# ESP32-H4 register map
Vendor: ESPRESSIF SYSTEMS (SHANGHAI) CO., LTD.; Series: ESP32 H-Series; File version: 1
CPU: RV32IMAC r0p0, little endian, no MPU, no FPU, 0 interrupt priority bits
Address unit: 32 bits
Registers are 32-bit, read-write, reset 0x0 unless marked. A register's access mark holds for its fields unless they carry their own. Offsets are from the block's base; [hi:lo] are bit positions.

## LP_PERI — LP_PERI Peripheral
Base 0x600B3400
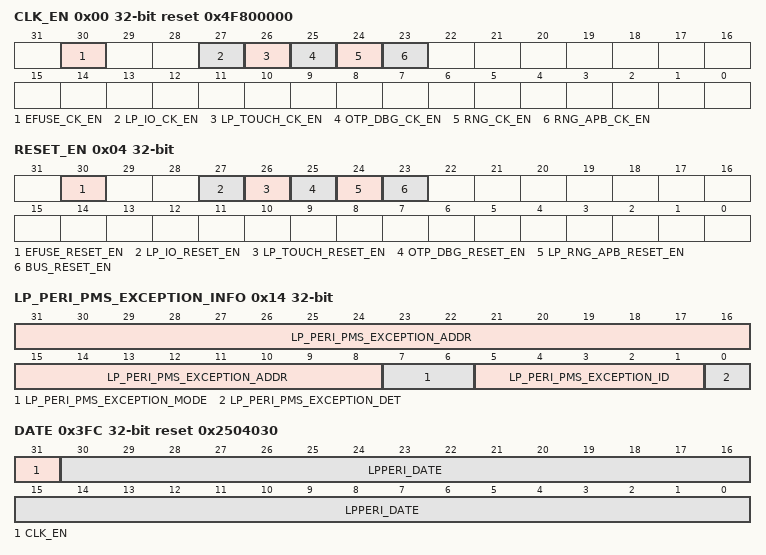
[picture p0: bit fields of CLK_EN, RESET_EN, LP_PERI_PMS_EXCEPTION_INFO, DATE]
0x00 CLK_EN reset 0x4F800000 — configure peri in lp system clk enable
  [30] EFUSE_CK_EN — efuse core clk enable 1: enable clock 0: disable clock
  [27] LP_IO_CK_EN — lp io clk enable 1: enable clock 0: disable clock
  [26] LP_TOUCH_CK_EN — lp touch clk enable 1: enable clock 0: disable clock
  [25] OTP_DBG_CK_EN — lp optdebug clk enable 1: enable clock 0: disable clock
  [24] RNG_CK_EN — lp rng clk enable 1: enable clock 0: disable clock
  [23] RNG_APB_CK_EN — lp rng apb clk enable 1: enable clock 0: disable clock
0x04 RESET_EN access per field — configure peri in lp system reset enable
  [30] EFUSE_RESET_EN rw — efuse core reset enable 1: enable reset 0: disable reset
  [27] LP_IO_RESET_EN rw — lp io reset enable 1: enable reset 0: disable reset
  [26] LP_TOUCH_RESET_EN rw — lp touch reset enable 1: enable reset 0: disable reset
  [25] OTP_DBG_RESET_EN rw — lp optdebug reset enable 1: enable reset 0: disable reset
  [24] LP_RNG_APB_RESET_EN rw — lp rng apb reset enable 1: enable reset 0: disable reset
  [23] BUS_RESET_EN wo — lp bus reset enable 1: enable reset 0: disable reset
0x10 LP_PERI_PMS_CONF wo — LP Peripherals PMS configuration register
  [0] LP_PERI_PMS_EXCEPTION_CLR — Configures whether or not to clear lp peri_pms_record_reg.\\ 0: No clear\\ 1: Clear peri_pms_record_reg\\
0x14 LP_PERI_PMS_EXCEPTION_INFO ro — LP Peripherals PMS exception info record register
  [31:8] LP_PERI_PMS_EXCEPTION_ADDR — Represents the access address (bit23~bit0) when lp peripheral pms has been triggered.\\
  [7:6] LP_PERI_PMS_EXCEPTION_MODE — Represents the security mode when lp peripheral pms has been triggered.\\
  [5:1] LP_PERI_PMS_EXCEPTION_ID — Represents the master id when lp peripheral pms has been triggered.\\
  [0] LP_PERI_PMS_EXCEPTION_DET — Represents whether the lp peripheral pms has been triggered.\\ 0: No triggered\\ 1: Has been triggered\\
0x18 PERI_PMS_INT_EN — APM interrupt enable register
  [0] LP_PERI_PMS_INT_EN — Configures to enable lp peri pms interrupt.\\ 0: disable \\ 1: enable \\
0x20 INTERRUPT_SOURCE ro — record the lp cpu interrupt
  [4:0] LP_INTERRUPT_SOURCE — BIT4~BIT0: pmu_lp_int, modem_lp_int, lp_timer_lp_int, lp_analog_peri_int, lp_io_int
0x3FC DATE reset 0x2504030 — version register
  [31] CLK_EN — force on reg clk
  [30:0] LPPERI_DATE — version register

## LP_ANA — LP_ANA Peripheral
Base 0x600B2C00
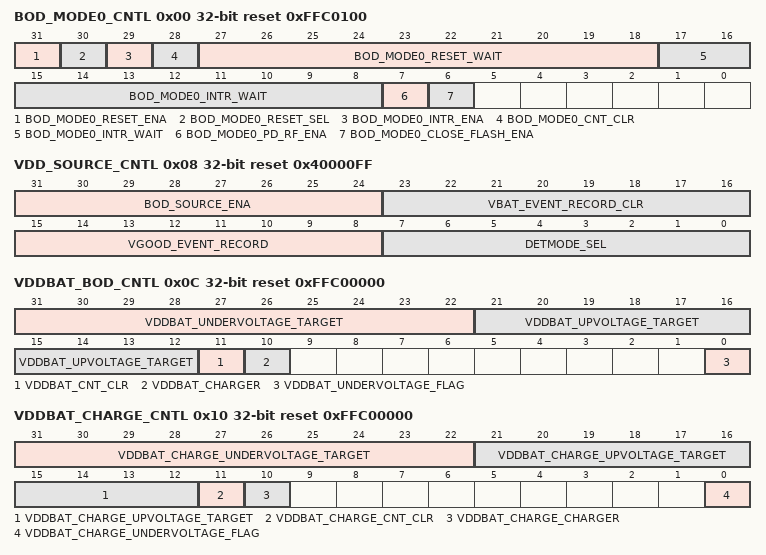
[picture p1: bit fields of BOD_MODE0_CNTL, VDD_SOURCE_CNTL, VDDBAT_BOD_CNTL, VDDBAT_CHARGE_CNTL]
0x00 BOD_MODE0_CNTL reset 0xFFC0100 — need_des
  [31] BOD_MODE0_RESET_ENA — need_des
  [30] BOD_MODE0_RESET_SEL — need_des
  [29] BOD_MODE0_INTR_ENA — need_des
  [28] BOD_MODE0_CNT_CLR — need_des
  [27:18] BOD_MODE0_RESET_WAIT — need_des
  [17:8] BOD_MODE0_INTR_WAIT — need_des
  [7] BOD_MODE0_PD_RF_ENA — need_des
  [6] BOD_MODE0_CLOSE_FLASH_ENA — need_des
0x04 BOD_MODE1_CNTL — need_des
  [31] BOD_MODE1_RESET_ENA
0x08 VDD_SOURCE_CNTL access per field reset 0x40000FF — need_des
  [31:24] BOD_SOURCE_ENA rw — need_des
  [23:16] VBAT_EVENT_RECORD_CLR wo — need_des
  [15:8] VGOOD_EVENT_RECORD ro — need_des
  [7:0] DETMODE_SEL rw — need_des
0x0C VDDBAT_BOD_CNTL access per field reset 0xFFC00000 — need_des
  [31:22] VDDBAT_UNDERVOLTAGE_TARGET rw — need_des
  [21:12] VDDBAT_UPVOLTAGE_TARGET rw — need_des
  [11] VDDBAT_CNT_CLR rw — need_des
  [10] VDDBAT_CHARGER rw — need_des
  [0] VDDBAT_UNDERVOLTAGE_FLAG ro — need_des
0x10 VDDBAT_CHARGE_CNTL access per field reset 0xFFC00000 — need_des
  [31:22] VDDBAT_CHARGE_UNDERVOLTAGE_TARGET rw — need_des
  [21:12] VDDBAT_CHARGE_UPVOLTAGE_TARGET rw — need_des
  [11] VDDBAT_CHARGE_CNT_CLR rw — need_des
  [10] VDDBAT_CHARGE_CHARGER rw — need_des
  [0] VDDBAT_CHARGE_UNDERVOLTAGE_FLAG ro — need_des
0x14 CK_GLITCH_CNTL — need_des
  [31] CK_GLITCH_RESET_ENA
0x18 PG_GLITCH_CNTL — need_des
  [31:26] POWER_GLITCH_RESET_ENA
0x1C FIB_ENABLE reset 0xFF000000 — need_des
  [31:24] ANA_FIB_ENA
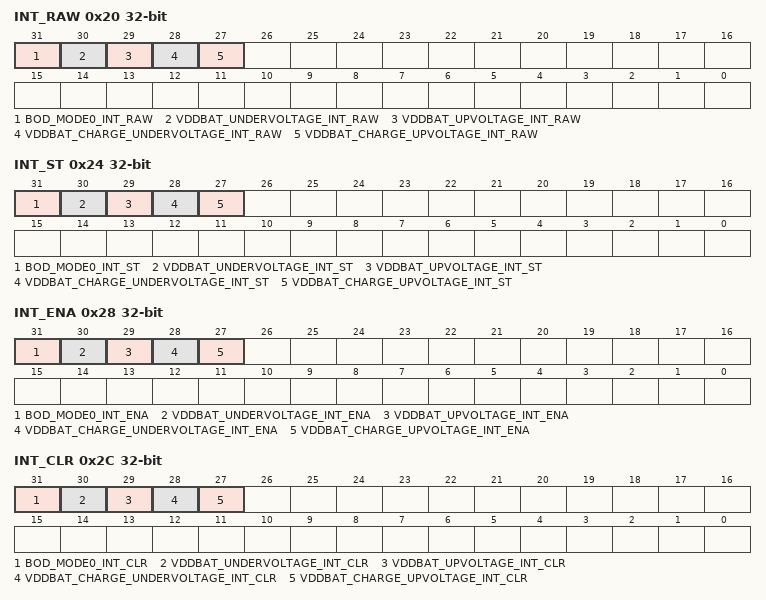
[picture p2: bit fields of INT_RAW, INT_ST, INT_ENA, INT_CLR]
0x20 INT_RAW — need_des
  [31] BOD_MODE0_INT_RAW — need_des
  [30] VDDBAT_UNDERVOLTAGE_INT_RAW — need_des
  [29] VDDBAT_UPVOLTAGE_INT_RAW — need_des
  [28] VDDBAT_CHARGE_UNDERVOLTAGE_INT_RAW — need_des
  [27] VDDBAT_CHARGE_UPVOLTAGE_INT_RAW — need_des
0x24 INT_ST ro — need_des
  [31] BOD_MODE0_INT_ST — need_des
  [30] VDDBAT_UNDERVOLTAGE_INT_ST — need_des
  [29] VDDBAT_UPVOLTAGE_INT_ST — need_des
  [28] VDDBAT_CHARGE_UNDERVOLTAGE_INT_ST — need_des
  [27] VDDBAT_CHARGE_UPVOLTAGE_INT_ST — need_des
0x28 INT_ENA — need_des
  [31] BOD_MODE0_INT_ENA — need_des
  [30] VDDBAT_UNDERVOLTAGE_INT_ENA — need_des
  [29] VDDBAT_UPVOLTAGE_INT_ENA — need_des
  [28] VDDBAT_CHARGE_UNDERVOLTAGE_INT_ENA — need_des
  [27] VDDBAT_CHARGE_UPVOLTAGE_INT_ENA — need_des
0x2C INT_CLR wo — need_des
  [31] BOD_MODE0_INT_CLR — need_des
  [30] VDDBAT_UNDERVOLTAGE_INT_CLR — need_des
  [29] VDDBAT_UPVOLTAGE_INT_CLR — need_des
  [28] VDDBAT_CHARGE_UNDERVOLTAGE_INT_CLR — need_des
  [27] VDDBAT_CHARGE_UPVOLTAGE_INT_CLR — need_des
0x30 LP_INT_RAW — need_des
  [31] BOD_MODE0_LP_INT_RAW
0x34 LP_INT_ST ro — need_des
  [31] BOD_MODE0_LP_INT_ST
0x38 LP_INT_ENA — need_des
  [31] BOD_MODE0_LP_INT_ENA
0x3C LP_INT_CLR wo — need_des
  [31] BOD_MODE0_LP_INT_CLR
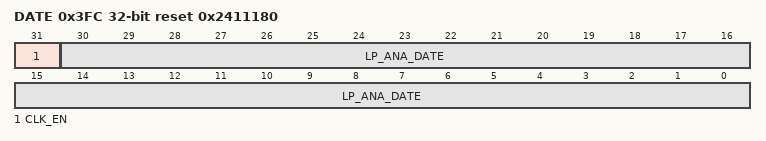
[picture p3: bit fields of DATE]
0x3FC DATE reset 0x2411180 — need_des
  [31] CLK_EN — need_des
  [30:0] LP_ANA_DATE — need_des
